# D2522AA register map
Vendor: Dialog; Series: D2522AA; File version: 1.2
CPU: CM0 r1p0, little endian, MPU, FPU, 3 interrupt priority bits
Registers are 32-bit, read-write, reset 0x0 unless marked. A register's access mark holds for its fields unless they carry their own. Offsets are from the block's base; [hi:lo] are bit positions; <NAME> marks a mode.

## SYS_WDOG — SYS_WDOG registers
Base 0x50000700
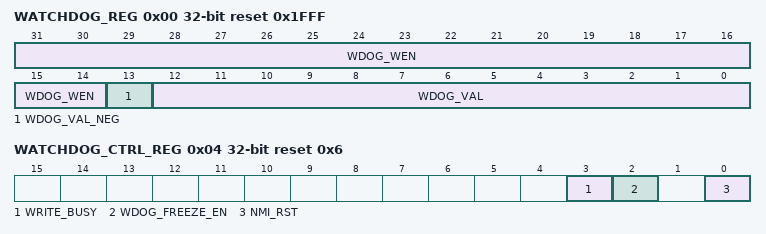
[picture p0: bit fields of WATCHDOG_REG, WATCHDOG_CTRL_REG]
0x00 WATCHDOG_REG reset 0x1FFF (reset mask 0x7FFFFFFF) — Watchdog timer register.
  [31:14] WDOG_WEN wo — Bit [31:14] = 0 = Write enable for Watchdog timer else Write disable. This filter prevents unintentional presetting the watchdog with a SW run-away.
  [13] WDOG_VAL_NEG — 0 = Watchdog timer value is positive. 1 = Watchdog timer value is negative.
  [12:0] WDOG_VAL — Write: Watchdog timer reload value. Note that all bits [31-14] must be 0 to reload this register. Read: Actual Watchdog timer value. Decremented by 1 every ~10 msec (RC32K) or ~29 msec(RCX). Bit 13 indicates a negative counter value. 2, 1, 0, 3FFF16, 3FFE16 etc. An NMI or WDOG (SYS) reset is generated under the following conditions: If WATCHDOG_CTRL_REG[NMI_RST] = 0 then If WDOG_VAL = 0 -> NMI (Non Maskable Interrupt) if WDOG_VAL =3FF016 -> WDOG reset -> reload 1FFF16 If WATCHDOG_CTRL_REG[NMI_RST] = 1 then if WDOG_VAL <= 0 -> WDOG reset -> reload 1FFF16 Note 1: The programmed value WDOG_VAL is updated in the (independent) Watchdog timer at the 2nd next RC32K or RCX clock tick. Note 2: Select RC32K or RCX with CLK_RCX_REG[RCX_ENABLE]. The RC32K is selected by default.
0x04 WATCHDOG_CTRL_REG reset 0x6 — Watchdog control register.
  [3] WRITE_BUSY ro — 0 = A new WATCHDOG_REG[WDOG_VAL] can be written. 1 = No new WATCHDOG_REG[WDOG_VAL] can be written. Note: It takes some time before the programmed WDOG_VAL is updated in the (independent) Watchdog timer. During this time it is not possible to write a new value to WATCHDOG_REG[WDOG_VAL].
  [2] WDOG_FREEZE_EN — 0 = Watchdog timer can not be frozen when NMI_RST=0. 1 = Watchdog timer can be frozen/resumed using SET_FREEZE_REG[FRZ_WDOG]/ RESET_FREEZE_REG[FRZ_WDOG] when NMI_RST=0.
  [0] NMI_RST — 0 = Watchdog timer generates NMI at value 0, and WDOG (SYS) reset at <= -16. Timer can be frozen/resumed using SET_FREEZE_REG[FRZ_WDOG]/ RESET_FREEZE_REG[FRZ_WDOG]. 1 = Watchdog timer generates a WDOG (SYS) reset at value 0 and can not be frozen by Software. Note that this bit can only be set to 1 by SW and only be reset with a WDOG (SYS) reset or SW reset. The watchdog is always frozen when the Cortex-M33 is halted in DEBUG State.

## TRNG — TRNG registers
Base 0x50040C00
0x00 TRNG_CTRL_REG — TRNG control register
  [0] TRNG_ENABLE — 0: Disable the TRNG 1: Enable the TRNG this signal is ignored when the FIFO is full
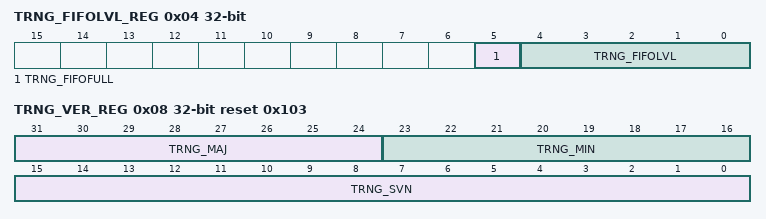
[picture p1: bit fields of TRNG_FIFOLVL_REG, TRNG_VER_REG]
0x04 TRNG_FIFOLVL_REG — TRNG FIFO level register
  [5] TRNG_FIFOFULL ro — 1:FIFO full indication. This bit is cleared if the FIFO is read.
  [4:0] TRNG_FIFOLVL ro — Number of 32 bit words of random data in the FIFO (max 31) until the FIFO is full. When it is 0 and TRNG_FIFOFULL is 1, it means the FIFO is full.
0x08 TRNG_VER_REG reset 0x103 (reset mask 0x7FFFFFFF) — TRNG Version register
  [31:24] TRNG_MAJ ro — Major version number
  [23:16] TRNG_MIN ro — Minor version number
  [15:0] TRNG_SVN ro — SVN revision number

## WAKEUP — WAKEUP registers
Base 0x50000100
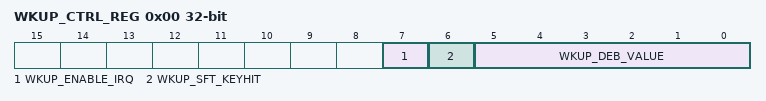
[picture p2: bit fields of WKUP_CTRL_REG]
0x00 WKUP_CTRL_REG — Control register for the wakeup counter
  [7] WKUP_ENABLE_IRQ — 0: no interrupt will be enabled 1: if you have an event an IRQ will be generated
  [6] WKUP_SFT_KEYHIT — 0 = no effect 1 = emulate key hit. First make this bit 0 before any new key hit can be sensed.
  [5:0] WKUP_DEB_VALUE — Wakeup debounce time. If set to 0, no debouncing will be done. Debounce time: N*1 ms. N =1..63
0x08 WKUP_RESET_IRQ_REG — Reset wakeup interrupt
  [15:0] WKUP_IRQ_RST wo — writing any value to this register will reset the interrupt. reading always returns 0.
0x14 WKUP_SELECT_P0_REG (reset mask 0x7FFFFFFF) — select which inputs from P0 port can trigger wkup counter
  [31:0] WKUP_SELECT_P0 — 0: input P0_xx is not enabled for wakeup event 1: input P0_xx is enabled for wakeup event
0x18 WKUP_SELECT_P1_REG — select which inputs from P1 port can trigger wkup counter
  [22:0] WKUP_SELECT_P1 — 0: input P1_xx is not enabled for wakeup event 1: input P1_xx is enabled for wakeup event
0x28 WKUP_POL_P0_REG (reset mask 0x7FFFFFFF) — select the sesitivity polarity for each P0 input
  [31:0] WKUP_POL_P0 — 0: enabled input P0_xx will give an event if that input goes high 1: enabled input P0_xx will give an event if that input goes low
0x2C WKUP_POL_P1_REG — select the sesitivity polarity for each P1 input
  [22:0] WKUP_POL_P1 — 0: enabled input P1_xx will give an event if that input goes high 1: enabled input P1_xx will give an event if that input goes low
0x3C WKUP_STATUS_P0_REG (reset mask 0x7FFFFFFF) — Event status register for P0 and P1
  [31:0] WKUP_STAT_P0 ro — Contains the latched value of any toggle of the GPIOs Port P0. WKUP_STAT_P0[0] -> P0_00.
0x40 WKUP_STATUS_P1_REG — Event status register for P2
  [22:0] WKUP_STAT_P1 ro — Contains the latched value of any toggle of the GPIOs Port P1 WKUP_STATUS_1[0] -> P1_00.
0x48 WKUP_CLEAR_P0_REG (reset mask 0x7FFFFFFF) — Clear event register for P0 and P1
  [31:0] WKUP_CLEAR_P0 wo — Clear latched value of the GPIOs P0 when corresponding bit is 1
0x4C WKUP_CLEAR_P1_REG — Clear event register for P2
  [22:0] WKUP_CLEAR_P1 wo — Clear latched value of the GPIOs P1 when corresponding bit is 1
0x54 WKUP_SEL_GPIO_P0_REG (reset mask 0x7FFFFFFF) — select which inputs from P0 port can trigger interrupt
  [31:0] WKUP_SEL_GPIO_P0 — 0: input P0_xx is not enabled for GPIO interrupt 1: input P0_xx is enabled for GPIO interrupt
0x58 WKUP_SEL_GPIO_P1_REG — select which inputs from P1 port can trigger interrupt
  [22:0] WKUP_SEL_GPIO_P1 — 0: input P1_xx is not enabled for GPIO interrupt 1: input P1_xx is enabled for GPIO interrupt
